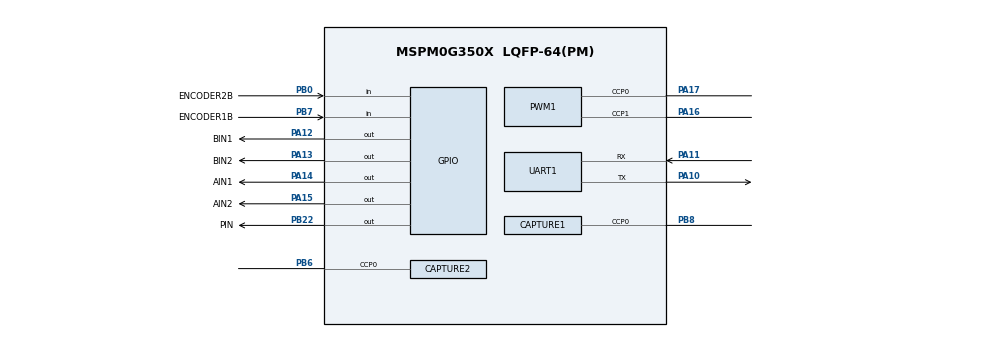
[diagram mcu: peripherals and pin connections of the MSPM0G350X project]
/**
 * @cliArgs --device "MSPM0G350X" --part "Default" --package "LQFP-64(PM)" --product "mspm0_sdk@2.05.01.01"
 * @versions {"tool":"1.24.0+4110"}
 */

/**
 * Import the modules used in this configuration.
 */
const CAPTURE  = scripting.addModule("/ti/driverlib/CAPTURE", {}, false);
const CAPTURE1 = CAPTURE.addInstance();
const CAPTURE2 = CAPTURE.addInstance();
const GPIO     = scripting.addModule("/ti/driverlib/GPIO", {}, false);
const GPIO1    = GPIO.addInstance();
const GPIO2    = GPIO.addInstance();
const GPIO3    = GPIO.addInstance();
const PWM      = scripting.addModule("/ti/driverlib/PWM", {}, false);
const PWM1     = PWM.addInstance();
const SYSCTL   = scripting.addModule("/ti/driverlib/SYSCTL");
const TIMER    = scripting.addModule("/ti/driverlib/TIMER", {}, false);
const TIMER1   = TIMER.addInstance();
const UART     = scripting.addModule("/ti/driverlib/UART", {}, false);
const UART1    = UART.addInstance();

/**
 * Write custom configuration values to the imported modules.
 */
const divider9       = system.clockTree["UDIV"];
divider9.divideValue = 2;

const mux4       = system.clockTree["EXHFMUX"];
mux4.inputSelect = "EXHFMUX_XTAL";

const mux8       = system.clockTree["HSCLKMUX"];
mux8.inputSelect = "HSCLKMUX_SYSPLL2X";

const mux12       = system.clockTree["SYSPLLMUX"];
mux12.inputSelect = "zSYSPLLMUX_HFCLK";

const pinFunction4        = system.clockTree["HFXT"];
pinFunction4.inputFreq    = 40;
pinFunction4.enable       = true;
pinFunction4.HFCLKMonitor = true;
pinFunction4.HFXTStartup  = 20;

CAPTURE1.$name                              = "ENCODER1A";
CAPTURE1.timerPeriod                        = "0.1 ms";
CAPTURE1.interrupts                         = ["CC0_DN"];
CAPTURE1.timerClkPrescale                   = 256;
CAPTURE1.filterPeriod                       = "PER_8";
CAPTURE1.timerStartTimer                    = true;
CAPTURE1.peripheral.$assign                 = "TIMA0";
CAPTURE1.peripheral.ccp0Pin.$assign         = "PB8";
CAPTURE1.ccp0PinConfig.hideOutputInversion  = scripting.forceWrite(false);
CAPTURE1.ccp0PinConfig.onlyInternalResistor = scripting.forceWrite(false);
CAPTURE1.ccp0PinConfig.passedPeripheralType = scripting.forceWrite("Digital");
CAPTURE1.ccp0PinConfig.$name                = "ti_driverlib_gpio_GPIOPinGeneric4";

const Board = scripting.addModule("/ti/driverlib/Board", {}, false);

CAPTURE2.timerClkPrescale                   = 256;
CAPTURE2.timerPeriod                        = "0.1 ms";
CAPTURE2.$name                              = "ENCODER2A";
CAPTURE2.filterPeriod                       = "PER_8";
CAPTURE2.interrupts                         = ["CC0_DN"];
CAPTURE2.timerStartTimer                    = true;
CAPTURE2.peripheral.$assign                 = "TIMG6";
CAPTURE2.peripheral.ccp0Pin.$assign         = "PB6";
CAPTURE2.ccp0PinConfig.hideOutputInversion  = scripting.forceWrite(false);
CAPTURE2.ccp0PinConfig.onlyInternalResistor = scripting.forceWrite(false);
CAPTURE2.ccp0PinConfig.passedPeripheralType = scripting.forceWrite("Digital");
CAPTURE2.ccp0PinConfig.$name                = "ti_driverlib_gpio_GPIOPinGeneric5";

GPIO1.$name                          = "LED";
GPIO1.associatedPins[0].$name        = "PIN";
GPIO1.associatedPins[0].ioStructure  = "SD";
GPIO1.associatedPins[0].assignedPort = "PORTB";
GPIO1.associatedPins[0].assignedPin  = "22";
GPIO1.associatedPins[0].pin.$assign  = "PB22";

GPIO2.$name                          = "TB6612";
GPIO2.port                           = "PORTA";
GPIO2.associatedPins.create(4);
GPIO2.associatedPins[0].$name        = "AIN1";
GPIO2.associatedPins[0].initialValue = "SET";
GPIO2.associatedPins[0].assignedPin  = "14";
GPIO2.associatedPins[0].pin.$assign  = "PA14";
GPIO2.associatedPins[1].$name        = "AIN2";
GPIO2.associatedPins[1].initialValue = "SET";
GPIO2.associatedPins[1].assignedPin  = "15";
GPIO2.associatedPins[1].pin.$assign  = "PA15";
GPIO2.associatedPins[2].$name        = "BIN1";
GPIO2.associatedPins[2].initialValue = "SET";
GPIO2.associatedPins[2].assignedPin  = "12";
GPIO2.associatedPins[2].pin.$assign  = "PA12";
GPIO2.associatedPins[3].$name        = "BIN2";
GPIO2.associatedPins[3].initialValue = "SET";
GPIO2.associatedPins[3].assignedPin  = "13";
GPIO2.associatedPins[3].pin.$assign  = "PA13";

GPIO3.$name                          = "GPIO_ENCODER";
GPIO3.associatedPins.create(2);
GPIO3.associatedPins[0].$name        = "ENCODER1B";
GPIO3.associatedPins[0].direction    = "INPUT";
GPIO3.associatedPins[0].assignedPort = "PORTB";
GPIO3.associatedPins[0].assignedPin  = "7";
GPIO3.associatedPins[0].interruptEn  = true;
GPIO3.associatedPins[0].polarity     = "RISE";
GPIO3.associatedPins[0].pin.$assign  = "PB7";
GPIO3.associatedPins[1].$name        = "ENCODER2B";
GPIO3.associatedPins[1].direction    = "INPUT";
GPIO3.associatedPins[1].assignedPort = "PORTB";
GPIO3.associatedPins[1].assignedPin  = "0";
GPIO3.associatedPins[1].interruptEn  = true;
GPIO3.associatedPins[1].polarity     = "RISE";
GPIO3.associatedPins[1].pin.$assign  = "PB0";

PWM1.$name                      = "PWM_0";
PWM1.timerStartTimer            = true;
PWM1.clockDivider               = 8;
PWM1.peripheral.$assign         = "TIMA1";
PWM1.peripheral.ccp0Pin.$assign = "PA17";
PWM1.peripheral.ccp1Pin.$assign = "PA16";
PWM1.PWM_CHANNEL_0.$name        = "ti_driverlib_pwm_PWMTimerCC0";
PWM1.PWM_CHANNEL_0.invert       = true;
PWM1.PWM_CHANNEL_1.$name        = "ti_driverlib_pwm_PWMTimerCC1";
PWM1.PWM_CHANNEL_1.invert       = true;
PWM1.ccp0PinConfig.$name        = "ti_driverlib_gpio_GPIOPinGeneric2";
PWM1.ccp1PinConfig.$name        = "ti_driverlib_gpio_GPIOPinGeneric3";

SYSCTL.forceDefaultClkConfig = true;
SYSCTL.clockTreeEn           = true;
SYSCTL.validateClkStatus     = true;

TIMER1.$name              = "CLOCK";
TIMER1.timerClkPrescale   = 40;
TIMER1.interrupts         = ["ZERO"];
TIMER1.timerMode          = "PERIODIC";
TIMER1.timerStartTimer    = true;
TIMER1.timerPeriod        = "10 ms";
TIMER1.peripheral.$assign = "TIMG0";

UART1.$name                        = "UART_0";
UART1.targetBaudRate               = 115200;
UART1.peripheral.$assign           = "UART0";
UART1.peripheral.rxPin.$assign     = "PA11";
UART1.peripheral.txPin.$assign     = "PA10";
UART1.txPinConfig.$name            = "ti_driverlib_gpio_GPIOPinGeneric0";
UART1.txPinConfig.enableConfig     = true;
UART1.txPinConfig.internalResistor = "PULL_UP";
UART1.rxPinConfig.$name            = "ti_driverlib_gpio_GPIOPinGeneric1";
UART1.rxPinConfig.enableConfig     = true;
UART1.rxPinConfig.internalResistor = "PULL_UP";

/**
 * Pinmux solution for unlocked pins/peripherals. This ensures that minor changes to the automatic solver in a future
 * version of the tool will not impact the pinmux you originally saw.  These lines can be completely deleted in order to
 * re-solve from scratch.
 */
pinFunction4.peripheral.$suggestSolution           = "SYSCTL";
pinFunction4.peripheral.hfxInPin.$suggestSolution  = "PA5";
pinFunction4.peripheral.hfxOutPin.$suggestSolution = "PA6";
Board.peripheral.$suggestSolution                  = "DEBUGSS";
Board.peripheral.swclkPin.$suggestSolution         = "PA20";
Board.peripheral.swdioPin.$suggestSolution         = "PA19";
